# f280013x_input_xbar_regs register map
Vendor: Texas Instruments
Peripheral module from a debugger description file (folder C2000).
Address unit: 16 bits
Registers are 16-bit, read-write, no defined reset value unless marked. A register's access mark holds for its fields unless they carry their own. Offsets are as the file gives them; lines under a group give offsets from that group; [hi:lo] are bit positions; {n}, {i} and the like mark numbered series; 'fields as' and 'values as' point back to an identical list; <NAME> marks a mode.

## INPUT_XBAR_REGS — INPUT XBAR Registers
0x00 INPUT1SELECT — INPUT1 Input Select Register (GPIO0 to x)
  [15:0] SELECT — Select GPIO for INPUT1 signal
0x01 INPUT2SELECT — INPUT2 Input Select Register (GPIO0 to x)
  [15:0] SELECT — Select GPIO for INPUT2 signal
0x02 INPUT3SELECT — INPUT3 Input Select Register (GPIO0 to x)
  [15:0] SELECT — Select GPIO for INPUT3 signal
0x03 INPUT4SELECT — INPUT4 Input Select Register (GPIO0 to x)
  [15:0] SELECT — Select GPIO for INPUT4 signal
0x04 INPUT5SELECT — INPUT5 Input Select Register (GPIO0 to x)
  [15:0] SELECT — Select GPIO for INPUT5 signal
0x05 INPUT6SELECT — INPUT6 Input Select Register (GPIO0 to x)
  [15:0] SELECT — Select GPIO for INPUT6 signal
0x06 INPUT7SELECT — INPUT7 Input Select Register (GPIO0 to x)
  [15:0] SELECT — Select GPIO for INPUT7 signal
0x07 INPUT8SELECT — INPUT8 Input Select Register (GPIO0 to x)
  [15:0] SELECT — Select GPIO for INPUT8 signal
0x08 INPUT9SELECT — INPUT9 Input Select Register (GPIO0 to x)
  [15:0] SELECT — Select GPIO for INPUT9 signal
0x09 INPUT10SELECT — INPUT10 Input Select Register (GPIO0 to x)
  [15:0] SELECT — Select GPIO for INPUT10 signal
0x0A INPUT11SELECT — INPUT11 Input Select Register (GPIO0 to x)
  [15:0] SELECT — Select GPIO for INPUT11 signal
0x0B INPUT12SELECT — INPUT12 Input Select Register (GPIO0 to x)
  [15:0] SELECT — Select GPIO for INPUT12 signal
0x0C INPUT13SELECT — INPUT13 Input Select Register (GPIO0 to x)
  [15:0] SELECT — Select GPIO for INPUT13 signal
0x0D INPUT14SELECT — INPUT14 Input Select Register (GPIO0 to x)
  [15:0] SELECT — Select GPIO for INPUT14 signal
0x0E INPUT15SELECT — INPUT15 Input Select Register (GPIO0 to x)
  [15:0] SELECT — Select GPIO for INPUT15 signal
0x0F INPUT16SELECT — INPUT16 Input Select Register (GPIO0 to x)
  [15:0] SELECT — Select GPIO for INPUT16 signal
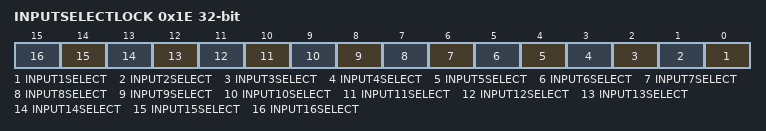
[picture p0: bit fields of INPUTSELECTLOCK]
0x1E INPUTSELECTLOCK 32-bit
  [n-1] INPUT{n}SELECT (n=1..16) — Lock bit for INPUT{n}SELECT Register
